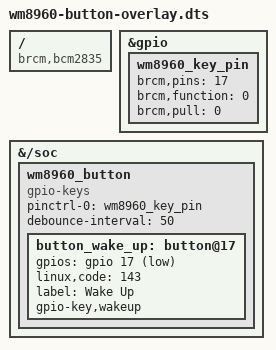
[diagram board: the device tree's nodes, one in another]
/dts-v1/;
/plugin/;

/ {
    compatible = "brcm,bcm2835", "brcm,bcm2708", "brcm,bcm2709";

    fragment@0 {
        target = <&gpio>;
        __overlay__ {
            wm8960_key_pin: wm8960_key_pin {
                brcm,pins = <17>;     
                brcm,function = <0>; /* input mode */
                brcm,pull = <0>;     /* pull up/down disabled */
            };
        };
    };

    fragment@1 {
        target-path = "/soc";
            __overlay__ {
                wm8960_button: wm8960_button {
                    compatible = "gpio-keys";
                    // #address-cells = <1>;
                    // #size-cells = <0>;
                    pinctrl-names = "default";
                    pinctrl-0 = <&wm8960_key_pin>;
                    status = "okay";
                    debounce-interval = <50>;

                    button_wake_up: button@17 {
                        gpios = <&gpio 17 1>;
                        linux,code = <143>; // KEY_WAKEUP
                        label = "Wake Up";
                        gpio-key,wakeup;
                    };
                };
            };
    };
};
